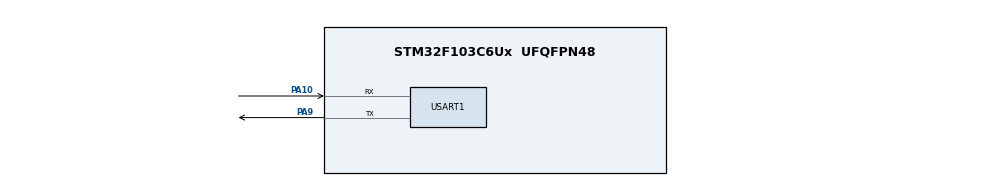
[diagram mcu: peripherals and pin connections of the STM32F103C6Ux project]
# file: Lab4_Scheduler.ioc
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Mcu.Family=STM32F1
Mcu.Name=STM32F103C6Ux
Mcu.Package=UFQFPN48
NVIC.PriorityGroup=NVIC_PRIORITYGROUP_4
NVIC.TIM2_IRQn=true\:0\:0\:false\:false\:true\:true\:true\:true
PA10.Mode=Asynchronous
PA10.Signal=USART1_RX
PA9.Mode=Asynchronous
PA9.Signal=USART1_TX
ProjectManager.HeapSize=0x200
ProjectManager.StackSize=0x400
ProjectManager.TargetToolchain=Makefile
RCC.APB1Freq_Value=8000000
RCC.APB2Freq_Value=8000000
TIM2.Period=9
TIM2.Prescaler=7999
USART1.VirtualMode=VM_ASYNC
VP_SYS_VS_ND.Mode=No_Debug
VP_TIM2_VS_ClockSourceINT.Mode=Internal
board=custom

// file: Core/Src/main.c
/* USER CODE BEGIN Header */
/**
  ******************************************************************************
  * @file           : main.c
  * @brief          : Main program body
  ******************************************************************************
  * @attention
  *
  * Copyright (c) 2026 STMicroelectronics.
  * All rights reserved.
  *
  * This software is licensed under terms that can be found in the LICENSE file
  * in the root directory of this software component.
  * If no LICENSE file comes with this software, it is provided AS-IS.
  *
  ******************************************************************************
  */
/* USER CODE END Header */
#include "main.h"

/* USER CODE BEGIN Includes */
#include "scheduler.h"
#include <stdio.h>
/* USER CODE END Includes */

TIM_HandleTypeDef htim2;

UART_HandleTypeDef huart1;

/* USER CODE BEGIN PV */
uint32_t task10msID = 0;
/* USER CODE END PV */

void SystemClock_Config(void);
static void MX_GPIO_Init(void);
static void MX_TIM2_Init(void);
static void MX_USART1_UART_Init(void);

/* USER CODE BEGIN 0 */

/* Print current time to Virtual Terminal */
void print_time(char *task_name)
{
    char buffer[64];

    int len = snprintf(
        buffer,
        sizeof(buffer),
        "[%lu ms] %s\r\n",
        (unsigned long)get_time(),
        task_name
    );

    if (len > 0 && len < sizeof(buffer))
    {
        HAL_UART_Transmit(
            &huart1,
            (uint8_t *)buffer,
            len,
            100
        );
    }
}

/* Task runs every 10ms */
void Task_10ms(void)
{
    print_time("Task 10ms");
}

/* Five required tasks */
void Task_500ms(void)
{
    print_time("Task 500ms");
}

void Task_1000ms(void)
{
    print_time("Task 1000ms");
}

void Task_1500ms(void)
{
    print_time("Task 1500ms");
}

void Task_2000ms(void)
{
    print_time("Task 2000ms");
}

void Task_2500ms(void)
{
    print_time("Task 2500ms");
}

/* Run only once */
void Task_OneShot(void)
{
    print_time("One-shot 750ms");
}

/* Delete Task_10ms after 3 seconds */
void Task_Stop10ms(void)
{
    if (SCH_Delete_Task(task10msID) == 1)
    {
        print_time("Deleted Task 10ms");
    }
}

/* USER CODE END 0 */

int main(void)
{

  /* MCU Configuration--------------------------------------------------------*/

  /* Reset of all peripherals, Initializes the Flash interface and the Systick. */
  HAL_Init();

  /* Configure the system clock */
  SystemClock_Config();

  /* Initialize all configured peripherals */
  MX_GPIO_Init();
  MX_TIM2_Init();
  MX_USART1_UART_Init();
  /* USER CODE BEGIN 2 */

  /* Initialize scheduler */
  SCH_Init();

  /* Callback every 10ms, starts after 100ms */
  task10msID = SCH_Add_Task(Task_10ms, 10, 1);

  /* Five periodic tasks */
  SCH_Add_Task(Task_500ms, 50, 50);
  SCH_Add_Task(Task_1000ms, 100, 100);
  SCH_Add_Task(Task_1500ms, 150, 150);
  SCH_Add_Task(Task_2000ms, 200, 200);
  SCH_Add_Task(Task_2500ms, 250, 250);

  /* One-shot task at 750ms */
  SCH_Add_Task(Task_OneShot, 75, 0);

  /* Delete 10ms callback at 3000ms */
  SCH_Add_Task(Task_Stop10ms, 300, 0);

  /* Start TIM2 interrupt */
  if (HAL_TIM_Base_Start_IT(&htim2) != HAL_OK)
  {
      Error_Handler();
  }

  /* USER CODE END 2 */

  /* Infinite loop */
  /* USER CODE BEGIN WHILE */
  while (1)
  {
    SCH_Dispatch_Tasks();
  }
  /* USER CODE END 3 */
}

void SystemClock_Config(void)
{
  RCC_OscInitTypeDef RCC_OscInitStruct = {0};
  RCC_ClkInitTypeDef RCC_ClkInitStruct = {0};

  /** Initializes the RCC Oscillators according to the specified parameters
  * in the RCC_OscInitTypeDef structure.
  */
  RCC_OscInitStruct.OscillatorType = RCC_OSCILLATORTYPE_HSI;
  RCC_OscInitStruct.HSIState = RCC_HSI_ON;
  RCC_OscInitStruct.HSICalibrationValue = RCC_HSICALIBRATION_DEFAULT;
  RCC_OscInitStruct.PLL.PLLState = RCC_PLL_NONE;
  if (HAL_RCC_OscConfig(&RCC_OscInitStruct) != HAL_OK)
  {
    Error_Handler();
  }

  /** Initializes the CPU, AHB and APB buses clocks
  */
  RCC_ClkInitStruct.ClockType = RCC_CLOCKTYPE_HCLK|RCC_CLOCKTYPE_SYSCLK
                              |RCC_CLOCKTYPE_PCLK1|RCC_CLOCKTYPE_PCLK2;
  RCC_ClkInitStruct.SYSCLKSource = RCC_SYSCLKSOURCE_HSI;
  RCC_ClkInitStruct.AHBCLKDivider = RCC_SYSCLK_DIV1;
  RCC_ClkInitStruct.APB1CLKDivider = RCC_HCLK_DIV1;
  RCC_ClkInitStruct.APB2CLKDivider = RCC_HCLK_DIV1;

  if (HAL_RCC_ClockConfig(&RCC_ClkInitStruct, FLASH_LATENCY_0) != HAL_OK)
  {
    Error_Handler();
  }
}

static void MX_TIM2_Init(void)
{

  TIM_ClockConfigTypeDef sClockSourceConfig = {0};
  TIM_MasterConfigTypeDef sMasterConfig = {0};

  htim2.Instance = TIM2;
  htim2.Init.Prescaler = 7999;
  htim2.Init.CounterMode = TIM_COUNTERMODE_UP;
  htim2.Init.Period = 9;
  htim2.Init.ClockDivision = TIM_CLOCKDIVISION_DIV1;
  htim2.Init.AutoReloadPreload = TIM_AUTORELOAD_PRELOAD_DISABLE;
  if (HAL_TIM_Base_Init(&htim2) != HAL_OK)
  {
    Error_Handler();
  }
  sClockSourceConfig.ClockSource = TIM_CLOCKSOURCE_INTERNAL;
  if (HAL_TIM_ConfigClockSource(&htim2, &sClockSourceConfig) != HAL_OK)
  {
    Error_Handler();
  }
  sMasterConfig.MasterOutputTrigger = TIM_TRGO_RESET;
  sMasterConfig.MasterSlaveMode = TIM_MASTERSLAVEMODE_DISABLE;
  if (HAL_TIMEx_MasterConfigSynchronization(&htim2, &sMasterConfig) != HAL_OK)
  {
    Error_Handler();
  }

}

static void MX_USART1_UART_Init(void)
{

  huart1.Instance = USART1;
  huart1.Init.BaudRate = 115200;
  huart1.Init.WordLength = UART_WORDLENGTH_8B;
  huart1.Init.StopBits = UART_STOPBITS_1;
  huart1.Init.Parity = UART_PARITY_NONE;
  huart1.Init.Mode = UART_MODE_TX_RX;
  huart1.Init.HwFlowCtl = UART_HWCONTROL_NONE;
  huart1.Init.OverSampling = UART_OVERSAMPLING_16;
  if (HAL_UART_Init(&huart1) != HAL_OK)
  {
    Error_Handler();
  }

}

static void MX_GPIO_Init(void)
{

  /* GPIO Ports Clock Enable */
  __HAL_RCC_GPIOA_CLK_ENABLE();

}

/* USER CODE BEGIN 4 */

void HAL_TIM_PeriodElapsedCallback(
    TIM_HandleTypeDef *htim
)
{
    if (htim->Instance == TIM2)
    {
        SCH_Update();
    }
}

/* USER CODE END 4 */

void Error_Handler(void)
{
  __disable_irq();
  while (1)
  {
  }
}
